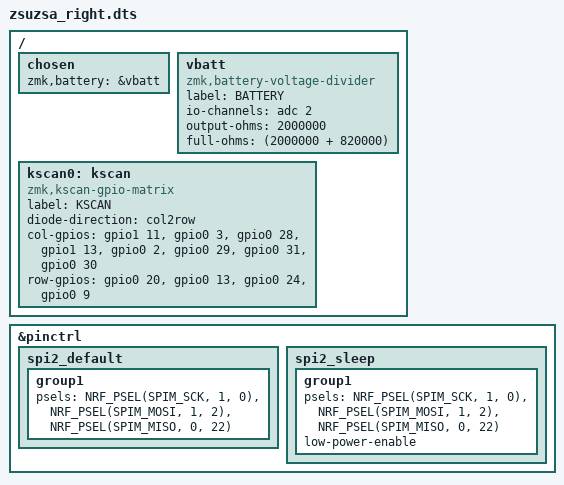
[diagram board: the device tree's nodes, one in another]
/*
* Copyright (c) 2023 CTDD
* SPDX-License-Identifier: MIT
*/

#include "zsuzsa.dtsi"

/{
    chosen {
        //zephyr,display = &epd; // uncomment this for display
        zmk,battery = &vbatt;
    };

    vbatt: vbatt {
        compatible = "zmk,battery-voltage-divider";
        label = "BATTERY";
        io-channels = <&adc 2>;
        output-ohms = <2000000>;
        full-ohms = <(2000000 + 820000)>; // 2M + 820k maybe need change
    };

    kscan0: kscan {
        compatible = "zmk,kscan-gpio-matrix";
        label = "KSCAN";

        diode-direction = "col2row";

        col-gpios
            = <&gpio1 11 GPIO_ACTIVE_HIGH>
            , <&gpio0 3 GPIO_ACTIVE_HIGH>
            , <&gpio0 28 GPIO_ACTIVE_HIGH>
            , <&gpio1 13 GPIO_ACTIVE_HIGH>
            , <&gpio0 2 GPIO_ACTIVE_HIGH>
            , <&gpio0 29 GPIO_ACTIVE_HIGH>
            , <&gpio0 31 GPIO_ACTIVE_HIGH>
            , <&gpio0 30 GPIO_ACTIVE_HIGH>
            ;

        row-gpios
            = <&gpio0 20 (GPIO_ACTIVE_HIGH | GPIO_PULL_DOWN)>
            , <&gpio0 13 (GPIO_ACTIVE_HIGH | GPIO_PULL_DOWN)>
            , <&gpio0 24 (GPIO_ACTIVE_HIGH | GPIO_PULL_DOWN)>
            , <&gpio0 9 (GPIO_ACTIVE_HIGH | GPIO_PULL_DOWN)>
            ;
    };
};

// TODO: edit for e-ink and spi

&pinctrl { // maybe pinctrl is not needed, test it
    spi2_default: spi2_default {
        group1 {
            psels = <NRF_PSEL(SPIM_SCK, 1, 0)>,
                <NRF_PSEL(SPIM_MOSI, 1, 2)>,
                <NRF_PSEL(SPIM_MISO, 0, 22)>;
        };
    };

    spi2_sleep: spi2_sleep {
        group1 {
            psels = <NRF_PSEL(SPIM_SCK, 1, 0)>,
                <NRF_PSEL(SPIM_MOSI, 1, 2)>,
                <NRF_PSEL(SPIM_MISO, 0, 22)>;
            low-power-enable;
        };
    };
}; // maybe need gpio for CE, not sure, test it x2
// need more gpio for BUSY, RST, not sure how to add yet

/*
*&spi2 {
*    status = "okay";
*    compatible = "nordic,nrf-spim";
*    pinctrl-0 = <&spi2_default>;
*    pinctrl-1 = <&spi2_sleep>;
*    pinctrl-names = "default", "sleep";
*    cs-gpios = <&gpio0 17 GPIO_ACTIVE_LOW>;
*
*    epd: il0323@0 {
*        compatible = "gooddisplay,il0323";
*        reg =  <0>;
*        label = "DISPLAY";
*        width = <80>;
*        height = <128>;
*        spi-max-frequency = <4000000>;
*        dc-gpios = <&gpio0 15 GPIO_ACTIVE_LOW>;
*        busy-gpios = <&gpio0 14 GPIO_ACTIVE_LOW>;
*        reset-gpios = <&gpio0 25 GPIO_ACTIVE_LOW>;
*        pwr = [03 00 26 26];
*        cdi = <0xd2>;
*        tcon = <0x22>;
*    };
*};
*/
